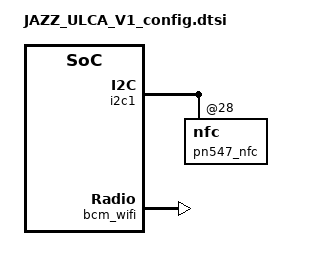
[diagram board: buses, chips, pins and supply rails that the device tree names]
/*
 * Hisilicon Ltd.
 *
 * A15x4 A7x4
 *
 * It is only a demo for hisilicon hi3630 board. You show change the
 * address of each node according to datasheet.
 */


/include/ "hisi_sim_hotplug.dtsi"

/include/ "JAZZ_ULG_V1_config.dtsi"
/include/ "hisi_3630_pin_JAZZ_ULCA_V1.dtsi"
/include/ "hisi_3630_modem_JAZZ_ULCA_V1.dtsi"
/ {
	board_info: board_info {
		hisi,boardid = <8 0 7>;
		hisi,boardname = "Jazz_UL+CA_V1";
		hisi,modem_id = <0x3fb06000>;
		hw,public;
	};
	amba {
		i2c1: i2c@FDF0A000 {
			pn547_nfc:nfc@28 {
					  nfc_nxp_name = "Jazz_ULCA_V1_libnfc-nxp.conf";
					  hw,public="nfc_nxp_name";
			};
		};
	};
	bcm_wifi {
		wifi_nvram_name = "nvram4334_hw_jazz_ulca.txt";
		wifi_fw_name = "fw_bcm4334_hw.bin";
		status = "ok";
	};
	sim0 {
		status = "ok";
	};
	audio_hal_config {
		aud_para = "JAZZ_ULCA";
	};
};
